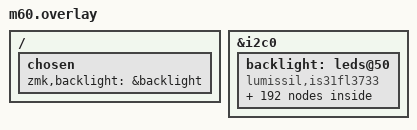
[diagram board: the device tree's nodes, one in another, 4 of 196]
/ {
	chosen {
        zmk,backlight = &backlight;
	};
};

&i2c0 {
    status = "okay";
    sda-pin = <37>;
    scl-pin = <38>;

    backlight: leds@50 {
        compatible = "lumissil,is31fl3733";
        reg = <0x50>;
        label = "backlight";

        power-gpios = <&gpio1 4 (GPIO_ACTIVE_HIGH)>;

        channel0 { channel = <0>; };
        channel1 { channel = <1>; };
        channel2 { channel = <2>; };
        channel3 { channel = <3>; };
        channel4 { channel = <4>; };
        channel5 { channel = <5>; };
        channel6 { channel = <6>; };
        channel7 { channel = <7>; };
        channel8 { channel = <8>; };
        channel9 { channel = <9>; };
        channel10 { channel = <10>; };
        channel11 { channel = <11>; };
        channel12 { channel = <12>; };
        channel13 { channel = <13>; };
        channel14 { channel = <14>; };
        channel15 { channel = <15>; };
        channel16 { channel = <16>; };
        channel17 { channel = <17>; };
        channel18 { channel = <18>; };
        channel19 { channel = <19>; };
        channel20 { channel = <20>; };
        channel21 { channel = <21>; };
        channel22 { channel = <22>; };
        channel23 { channel = <23>; };
        channel24 { channel = <24>; };
        channel25 { channel = <25>; };
        channel26 { channel = <26>; };
        channel27 { channel = <27>; };
        channel28 { channel = <28>; };
        channel29 { channel = <29>; };
        channel30 { channel = <30>; };
        channel31 { channel = <31>; };
        channel32 { channel = <32>; };
        channel33 { channel = <33>; };
        channel34 { channel = <34>; };
        channel35 { channel = <35>; };
        channel36 { channel = <36>; };
        channel37 { channel = <37>; };
        channel38 { channel = <38>; };
        channel39 { channel = <39>; };
        channel40 { channel = <40>; };
        channel41 { channel = <41>; };
        channel42 { channel = <42>; };
        channel43 { channel = <43>; };
        channel44 { channel = <44>; };
        channel45 { channel = <45>; };
        channel46 { channel = <46>; };
        channel47 { channel = <47>; };
        channel48 { channel = <48>; };
        channel49 { channel = <49>; };
        channel50 { channel = <50>; };
        channel51 { channel = <51>; };
        channel52 { channel = <52>; };
        channel53 { channel = <53>; };
        channel54 { channel = <54>; };
        channel55 { channel = <55>; };
        channel56 { channel = <56>; };
        channel57 { channel = <57>; };
        channel58 { channel = <58>; };
        channel59 { channel = <59>; };
        channel60 { channel = <60>; };
        channel61 { channel = <61>; };
        channel62 { channel = <62>; };
        channel63 { channel = <63>; };
        channel64 { channel = <64>; };
        channel65 { channel = <65>; };
        channel66 { channel = <66>; };
        channel67 { channel = <67>; };
        channel68 { channel = <68>; };
        channel69 { channel = <69>; };
        channel70 { channel = <70>; };
        channel71 { channel = <71>; };
        channel72 { channel = <72>; };
        channel73 { channel = <73>; };
        channel74 { channel = <74>; };
        channel75 { channel = <75>; };
        channel76 { channel = <76>; };
        channel77 { channel = <77>; };
        channel78 { channel = <78>; };
        channel79 { channel = <79>; };
        channel80 { channel = <80>; };
        channel81 { channel = <81>; };
        channel82 { channel = <82>; };
        channel83 { channel = <83>; };
        channel84 { channel = <84>; };
        channel85 { channel = <85>; };
        channel86 { channel = <86>; };
        channel87 { channel = <87>; };
        channel88 { channel = <88>; };
        channel89 { channel = <89>; };
        channel90 { channel = <90>; };
        channel91 { channel = <91>; };
        channel92 { channel = <92>; };
        channel93 { channel = <93>; };
        channel94 { channel = <94>; };
        channel95 { channel = <95>; };
        channel96 { channel = <96>; };
        channel97 { channel = <97>; };
        channel98 { channel = <98>; };
        channel99 { channel = <99>; };
        channel100 { channel = <100>; };
        channel101 { channel = <101>; };
        channel102 { channel = <102>; };
        channel103 { channel = <103>; };
        channel104 { channel = <104>; };
        channel105 { channel = <105>; };
        channel106 { channel = <106>; };
        channel107 { channel = <107>; };
        channel108 { channel = <108>; };
        channel109 { channel = <109>; };
        channel110 { channel = <110>; };
        channel111 { channel = <111>; };
        channel112 { channel = <112>; };
        channel113 { channel = <113>; };
        channel114 { channel = <114>; };
        channel115 { channel = <115>; };
        channel116 { channel = <116>; };
        channel117 { channel = <117>; };
        channel118 { channel = <118>; };
        channel119 { channel = <119>; };
        channel120 { channel = <120>; };
        channel121 { channel = <121>; };
        channel122 { channel = <122>; };
        channel123 { channel = <123>; };
        channel124 { channel = <124>; };
        channel125 { channel = <125>; };
        channel126 { channel = <126>; };
        channel127 { channel = <127>; };
        channel128 { channel = <128>; };
        channel129 { channel = <129>; };
        channel130 { channel = <130>; };
        channel131 { channel = <131>; };
        channel132 { channel = <132>; };
        channel133 { channel = <133>; };
        channel134 { channel = <134>; };
        channel135 { channel = <135>; };
        channel136 { channel = <136>; };
        channel137 { channel = <137>; };
        channel138 { channel = <138>; };
        channel139 { channel = <139>; };
        channel140 { channel = <140>; };
        channel141 { channel = <141>; };
        channel142 { channel = <142>; };
        channel143 { channel = <143>; };
        channel144 { channel = <144>; };
        channel145 { channel = <145>; };
        channel146 { channel = <146>; };
        channel147 { channel = <147>; };
        channel148 { channel = <148>; };
        channel149 { channel = <149>; };
        channel150 { channel = <150>; };
        channel151 { channel = <151>; };
        channel152 { channel = <152>; };
        channel153 { channel = <153>; };
        channel154 { channel = <154>; };
        channel155 { channel = <155>; };
        channel156 { channel = <156>; };
        channel157 { channel = <157>; };
        channel158 { channel = <158>; };
        channel159 { channel = <159>; };
        channel160 { channel = <160>; };
        channel161 { channel = <161>; };
        channel162 { channel = <162>; };
        channel163 { channel = <163>; };
        channel164 { channel = <164>; };
        channel165 { channel = <165>; };
        channel166 { channel = <166>; };
        channel167 { channel = <167>; };
        channel168 { channel = <168>; };
        channel169 { channel = <169>; };
        channel170 { channel = <170>; };
        channel171 { channel = <171>; };
        channel172 { channel = <172>; };
        channel173 { channel = <173>; };
        channel174 { channel = <174>; };
        channel175 { channel = <175>; };
        channel176 { channel = <176>; };
        channel177 { channel = <177>; };
        channel178 { channel = <178>; };
        channel179 { channel = <179>; };
        channel180 { channel = <180>; };
        channel181 { channel = <181>; };
        channel182 { channel = <182>; };
        channel183 { channel = <183>; };
        channel184 { channel = <184>; };
        channel185 { channel = <185>; };
        channel186 { channel = <186>; };
        channel187 { channel = <187>; };
        channel188 { channel = <188>; };
        channel189 { channel = <189>; };
        channel190 { channel = <190>; };
        channel191 { channel = <191>; };
    };
};
